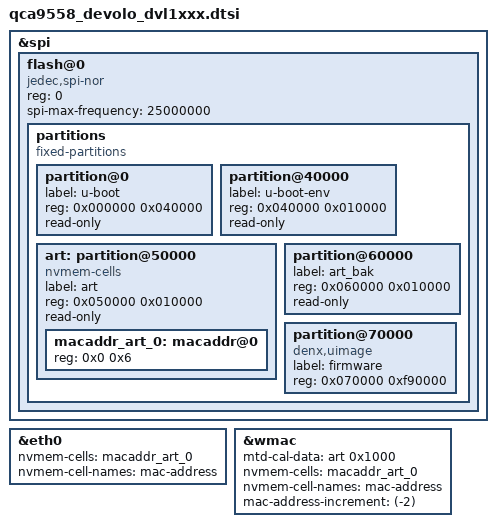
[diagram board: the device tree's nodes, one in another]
// SPDX-License-Identifier: GPL-2.0-or-later OR MIT

/*
 * The hardware of this board family is most likely shared with other devices
 * from other manufacturers.
 * Devolo seems to use hardware from Edimax, namely the Edimax WAP1750.
 *
 * The base board is identical but the single models differ in number of
 * buttons, ethernet ports, external console, USB, external / internal
 * antennas and number of spatial streams.
 */

#include "qca9558_edimax_wap1750.dtsi"

&spi {
	flash@0 {
		compatible = "jedec,spi-nor";
		reg = <0>;
		spi-max-frequency = <25000000>;

		partitions {
			compatible = "fixed-partitions";
			#address-cells = <1>;
			#size-cells = <1>;

			partition@0 {
				label = "u-boot";
				reg = <0x000000 0x040000>;
				read-only;
			};

			partition@40000 {
				label = "u-boot-env";
				reg = <0x040000 0x010000>;
				read-only;
			};

			art: partition@50000 {
				label = "art";
				reg = <0x050000 0x010000>;
				read-only;
			};

			partition@60000 {
				label = "art_bak";
				reg = <0x060000 0x010000>;
				read-only;
			};

			partition@70000 {
				compatible = "denx,uimage";
				label = "firmware";
				reg = <0x070000 0xf90000>;
			};
		};
	};
};

&eth0 {
	nvmem-cells = <&macaddr_art_0>;
	nvmem-cell-names = "mac-address";
};

&wmac {
	mtd-cal-data = <&art 0x1000>;
	nvmem-cells = <&macaddr_art_0>;
	nvmem-cell-names = "mac-address";
	mac-address-increment = <(-2)>;
};

&art {
	compatible = "nvmem-cells";
	#address-cells = <1>;
	#size-cells = <1>;

	macaddr_art_0: macaddr@0 {
		reg = <0x0 0x6>;
	};
};
